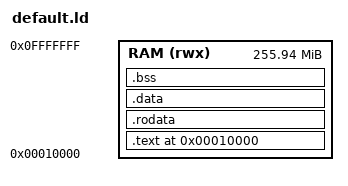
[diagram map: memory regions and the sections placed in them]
OUTPUT_ARCH("riscv")
ENTRY(_start)

MEMORY
{
    RAM (rwx) : ORIGIN = 0x00010000, LENGTH = 0x0FFF0000
}

SECTIONS
{
    .text 0x00010000 :
    {
        *(.text .text.*)
    } > RAM

    .rodata : ALIGN(4)
    {
        *(.rodata .rodata.*)
        *(.srodata .srodata.*)
    } > RAM

    .data : ALIGN(4)
    {
        *(.data .data.*)
        *(.sdata .sdata.*)
    } > RAM

    . = ALIGN(4);
    __global_pointer$ = . + 0x800;

    .bss (NOLOAD) : ALIGN(4)
    {
        __bss_start = .;
        *(.sbss .sbss.*)
        *(.bss .bss.*)
        *(COMMON)
        __bss_end = .;
    } > RAM

    . = ALIGN(4);
    _end = .;
    PROVIDE(end = .);

    . = 0x7FFFFFF0;
    __stack_top = .;
}
